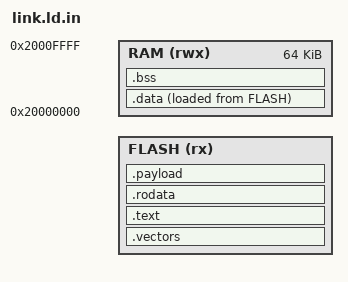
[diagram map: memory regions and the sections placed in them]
/* Linker script for the fictional Bench-MCU: 64 KiB flash, 64 KiB SRAM. */
ENTRY(Reset_Handler)
MEMORY
{
    FLASH (rx)  : ORIGIN = @FLASH_ORIGIN@, LENGTH = @FLASH_LEN@
    RAM   (rwx) : ORIGIN = 0x20000000, LENGTH = 64K
}
_estack = ORIGIN(RAM) + LENGTH(RAM);
SECTIONS
{
    .vectors : { KEEP(*(.vectors)) } > FLASH
    .text    : { *(.text*) . = ALIGN(4); } > FLASH
    .rodata  : { *(.rodata*) . = ALIGN(4); KEEP(*(.keystore)) . = ALIGN(4); } > FLASH
    .payload ALIGN(@PAYLOAD_ALIGN@) : { KEEP(*(.payload)) . = ALIGN(4); } > FLASH
    _sidata = LOADADDR(.data);
    .data    : { _sdata = .; *(.data*) . = ALIGN(4); _edata = .; } > RAM AT > FLASH
    .bss (NOLOAD) : { _sbss = .; *(.bss*) *(COMMON) . = ALIGN(4); _ebss = .; } > RAM
    /DISCARD/ : { *(.ARM.exidx*) *(.ARM.attributes) *(.comment) }
}
